AUTOSAR XML (schema 00046)
package /SwComponent
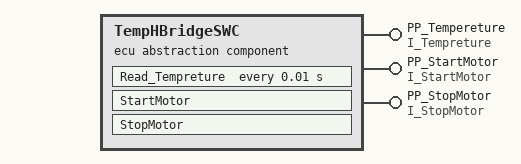
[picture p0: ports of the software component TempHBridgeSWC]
  ecu abstraction sw component type TempHBridgeSWC
    provide port PP_Tempereture: provided-interface=I_Tempreture
    provide port PP_StartMotor: provided-interface=I_StartMotor
    provide port PP_StopMotor: provided-interface=I_StopMotor
    behavior IB_SWC
      timing event TE_10ms: start-on-event=Read_Tempreture, period=0.01
      operation invoked event OIE_StartMotor: start-on-event=Start_Motor, operation=PP_StartMotor.StartMotor
      operation invoked event OIE_StopMotor: start-on-event=Stop_Motor, operation=PP_StopMotor.StopMotor
      runnable Read_Tempreture: can-be-invoked-concurrently=0, symbol=ReadTempreture_Function
        data-send-points:
          access VA_Temp: accessed-variable=PP_Tempereture.Tempreture
      runnable StartMotor: symbol=StartMotor_Function
      runnable StopMotor: symbol=StopMotor_Function
